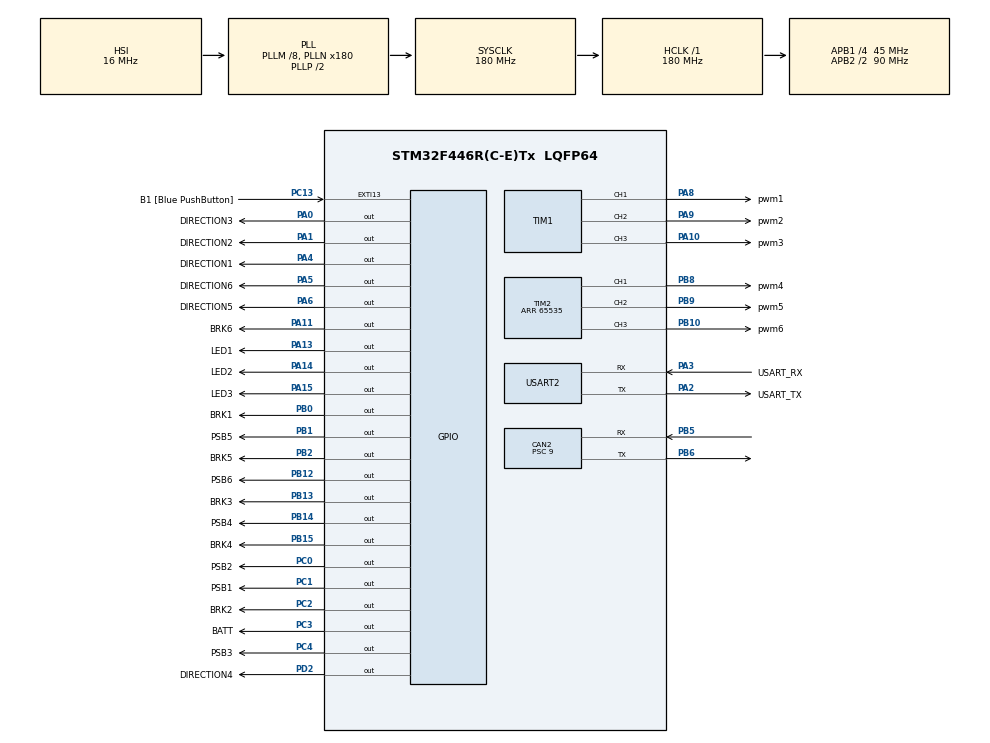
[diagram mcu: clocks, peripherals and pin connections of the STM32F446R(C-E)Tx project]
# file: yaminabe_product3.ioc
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CAN2.BS1=CAN_BS1_4TQ
CAN2.BS2=CAN_BS2_5TQ
CAN2.CalculateBaudRate=500000
CAN2.CalculateTimeBit=2000
CAN2.CalculateTimeQuantum=200.0
CAN2.Prescaler=9
CAN2.SJW=CAN_SJW_4TQ
Mcu.Family=STM32F4
Mcu.Name=STM32F446R(C-E)Tx
Mcu.Package=LQFP64
NVIC.CAN2_RX0_IRQn=true\:0\:0\:false\:false\:true\:true\:true\:true
NVIC.CAN2_RX1_IRQn=true\:0\:0\:false\:false\:true\:true\:true\:true
NVIC.CAN2_TX_IRQn=true\:0\:0\:false\:false\:true\:true\:true\:true
NVIC.PriorityGroup=NVIC_PRIORITYGROUP_0
PA0-WKUP.GPIO_Label=DIRECTION3
PA0-WKUP.Signal=GPIO_Output
PA1.GPIO_Label=DIRECTION2
PA1.Signal=GPIO_Output
PA10.GPIO_Label=pwm3
PA10.Signal=S_TIM1_CH3
PA11.GPIO_Label=BRK6
PA11.Signal=GPIO_Output
PA13.GPIO_Label=LED1
PA13.Signal=GPIO_Output
PA14.GPIO_Label=LED2
PA14.Signal=GPIO_Output
PA15.GPIO_Label=LED3
PA15.Signal=GPIO_Output
PA2.GPIO_Label=USART_TX
PA2.Mode=Asynchronous
PA2.Signal=USART2_TX
PA3.GPIO_Label=USART_RX
PA3.Mode=Asynchronous
PA3.Signal=USART2_RX
PA4.GPIO_Label=DIRECTION1
PA4.Signal=GPIO_Output
PA5.GPIO_Label=DIRECTION6
PA5.Signal=GPIO_Output
PA6.GPIO_Label=DIRECTION5
PA6.Signal=GPIO_Output
PA8.GPIO_Label=pwm1
PA8.Signal=S_TIM1_CH1
PA9.GPIO_Label=pwm2
PA9.Signal=S_TIM1_CH2
PB0.GPIO_Label=BRK1
PB0.Signal=GPIO_Output
PB1.GPIO_Label=PSB5
PB1.Signal=GPIO_Output
PB10.GPIO_Label=pwm6
PB10.Signal=S_TIM2_CH3
PB12.GPIO_Label=PSB6
PB12.Signal=GPIO_Output
PB13.GPIO_Label=BRK3
PB13.Signal=GPIO_Output
PB14.GPIO_Label=PSB4
PB14.Signal=GPIO_Output
PB15.GPIO_Label=BRK4
PB15.Signal=GPIO_Output
PB2.GPIO_Label=BRK5
PB2.Signal=GPIO_Output
PB3.Signal=SYS_JTDO-SWO
PB5.Mode=CAN_Activate
PB5.Signal=CAN2_RX
PB6.Mode=CAN_Activate
PB6.Signal=CAN2_TX
PB8.GPIO_Label=pwm4
PB8.Signal=S_TIM2_CH1_ETR
PB9.GPIO_Label=pwm5
PB9.Signal=S_TIM2_CH2
PC0.GPIO_Label=PSB2
PC0.Signal=GPIO_Output
PC1.GPIO_Label=PSB1
PC1.Signal=GPIO_Output
PC13.GPIO_Label=B1 [Blue PushButton]
PC13.GPIO_ModeDefaultEXTI=GPIO_MODE_IT_FALLING
PC13.Signal=GPXTI13
PC14-OSC32_IN.Mode=LSE-External-Oscillator
PC14-OSC32_IN.Signal=RCC_OSC32_IN
PC15-OSC32_OUT.Mode=LSE-External-Oscillator
PC15-OSC32_OUT.Signal=RCC_OSC32_OUT
PC2.GPIO_Label=BRK2
PC2.Signal=GPIO_Output
PC3.GPIO_Label=BATT
PC3.Signal=GPIO_Output
PC4.GPIO_Label=PSB3
PC4.Signal=GPIO_Output
PD2.GPIO_Label=DIRECTION4
PD2.Signal=GPIO_Output
PH0-OSC_IN.Mode=HSE-External-Oscillator
PH0-OSC_IN.Signal=RCC_OSC_IN
PH1-OSC_OUT.Mode=HSE-External-Oscillator
PH1-OSC_OUT.Signal=RCC_OSC_OUT
ProjectManager.HeapSize=0x200
ProjectManager.StackSize=0x400
ProjectManager.TargetToolchain=STM32CubeIDE
RCC.48MHZClocksFreq_Value=84000000
RCC.AHBFreq_Value=180000000
RCC.APB1CLKDivider=RCC_HCLK_DIV4
RCC.APB1Freq_Value=45000000
RCC.APB1TimFreq_Value=90000000
RCC.APB2CLKDivider=RCC_HCLK_DIV2
RCC.APB2Freq_Value=90000000
RCC.APB2TimFreq_Value=180000000
RCC.CortexFreq_Value=180000000
RCC.FLatency-AdvancedSettings=FLASH_LATENCY_5
RCC.HCLKFreq_Value=180000000
RCC.HSE_VALUE=8000000
RCC.HSI_VALUE=16000000
RCC.PLLM=8
RCC.PLLN=180
RCC.SYSCLKFreq_VALUE=180000000
RCC.SYSCLKSource=RCC_SYSCLKSOURCE_PLLCLK
RCC.USBFreq_Value=180000000
RCC.VCOOutputFreq_Value=360000000
SH.S_TIM1_CH1.0=TIM1_CH1,PWM Generation1 CH1
SH.S_TIM1_CH2.0=TIM1_CH2,PWM Generation2 CH2
SH.S_TIM1_CH3.0=TIM1_CH3,PWM Generation3 CH3
SH.S_TIM2_CH1_ETR.0=TIM2_CH1,PWM Generation1 CH1
SH.S_TIM2_CH2.0=TIM2_CH2,PWM Generation2 CH2
SH.S_TIM2_CH3.0=TIM2_CH3,PWM Generation3 CH3
TIM1.Channel-PWM\ Generation1\ CH1=TIM_CHANNEL_1
TIM1.Channel-PWM\ Generation2\ CH2=TIM_CHANNEL_2
TIM1.Channel-PWM\ Generation3\ CH3=TIM_CHANNEL_3
TIM2.Channel-PWM\ Generation1\ CH1=TIM_CHANNEL_1
TIM2.Channel-PWM\ Generation2\ CH2=TIM_CHANNEL_2
TIM2.Channel-PWM\ Generation3\ CH3=TIM_CHANNEL_3
TIM2.Period=65535
USART2.VirtualMode=VM_ASYNC
VP_TIM1_VS_ClockSourceINT.Mode=Internal
VP_TIM2_VS_ClockSourceINT.Mode=Internal
board=NUCLEO-F446RE

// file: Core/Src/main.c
/* USER CODE BEGIN Header */
/**
  ******************************************************************************
  * @file           : main.c
  * @brief          : Main program body
  ******************************************************************************
  * @attention
  *
  * Copyright (c) 2023 STMicroelectronics.
  * All rights reserved.
  *
  * This software is licensed under terms that can be found in the LICENSE file
  * in the root directory of this software component.
  * If no LICENSE file comes with this software, it is provided AS-IS.
  *
  ******************************************************************************
  */
/* USER CODE END Header */
#include "main.h"

CAN_HandleTypeDef hcan2;

TIM_HandleTypeDef htim1;
TIM_HandleTypeDef htim2;

UART_HandleTypeDef huart2;

void SystemClock_Config(void);
static void MX_GPIO_Init(void);
static void MX_USART2_UART_Init(void);
static void MX_TIM1_Init(void);
static void MX_TIM2_Init(void);
static void MX_CAN2_Init(void);

int main(void)
{

  /* MCU Configuration--------------------------------------------------------*/

  /* Reset of all peripherals, Initializes the Flash interface and the Systick. */
  HAL_Init();

  /* Configure the system clock */
  SystemClock_Config();

  /* Initialize all configured peripherals */
  MX_GPIO_Init();
  MX_USART2_UART_Init();
  MX_TIM1_Init();
  MX_TIM2_Init();
  MX_CAN2_Init();
  /* USER CODE BEGIN 2 */
  HAL_TIM_PWM_Start(&htim1, TIM_CHANNEL_1);
  HAL_TIM_PWM_Start(&htim1, TIM_CHANNEL_2);
  /* USER CODE END 2 */

  /* Infinite loop */
  /* USER CODE BEGIN WHILE */
  while (1)
  {
	  HAL_GPIO_WritePin(GPIOC,PSB1_Pin,GPIO_PIN_SET);
	  HAL_GPIO_WritePin(GPIOB,BRK1_Pin,GPIO_PIN_RESET);
	  HAL_GPIO_WritePin(GPIOA,DIRECTION1_Pin,GPIO_PIN_SET);
	  __HAL_TIM_SET_COMPARE(&htim1, TIM_CHANNEL_1,60000);
	  HAL_Delay(1000);
	  HAL_GPIO_WritePin(GPIOA,DIRECTION1_Pin,GPIO_PIN_RESET);
	  __HAL_TIM_SET_COMPARE(&htim1, TIM_CHANNEL_1,30000);
	  HAL_Delay(1000);

    /* USER CODE END WHILE */

  }
}

void SystemClock_Config(void)
{
  RCC_OscInitTypeDef RCC_OscInitStruct = {0};
  RCC_ClkInitTypeDef RCC_ClkInitStruct = {0};

  /** Configure the main internal regulator output voltage
  */
  __HAL_RCC_PWR_CLK_ENABLE();
  __HAL_PWR_VOLTAGESCALING_CONFIG(PWR_REGULATOR_VOLTAGE_SCALE1);

  /** Initializes the RCC Oscillators according to the specified parameters
  * in the RCC_OscInitTypeDef structure.
  */
  RCC_OscInitStruct.OscillatorType = RCC_OSCILLATORTYPE_HSI;
  RCC_OscInitStruct.HSIState = RCC_HSI_ON;
  RCC_OscInitStruct.HSICalibrationValue = RCC_HSICALIBRATION_DEFAULT;
  RCC_OscInitStruct.PLL.PLLState = RCC_PLL_ON;
  RCC_OscInitStruct.PLL.PLLSource = RCC_PLLSOURCE_HSI;
  RCC_OscInitStruct.PLL.PLLM = 8;
  RCC_OscInitStruct.PLL.PLLN = 180;
  RCC_OscInitStruct.PLL.PLLP = RCC_PLLP_DIV2;
  RCC_OscInitStruct.PLL.PLLQ = 2;
  RCC_OscInitStruct.PLL.PLLR = 2;
  if (HAL_RCC_OscConfig(&RCC_OscInitStruct) != HAL_OK)
  {
    Error_Handler();
  }

  /** Activate the Over-Drive mode
  */
  if (HAL_PWREx_EnableOverDrive() != HAL_OK)
  {
    Error_Handler();
  }

  /** Initializes the CPU, AHB and APB buses clocks
  */
  RCC_ClkInitStruct.ClockType = RCC_CLOCKTYPE_HCLK|RCC_CLOCKTYPE_SYSCLK
                              |RCC_CLOCKTYPE_PCLK1|RCC_CLOCKTYPE_PCLK2;
  RCC_ClkInitStruct.SYSCLKSource = RCC_SYSCLKSOURCE_PLLCLK;
  RCC_ClkInitStruct.AHBCLKDivider = RCC_SYSCLK_DIV1;
  RCC_ClkInitStruct.APB1CLKDivider = RCC_HCLK_DIV4;
  RCC_ClkInitStruct.APB2CLKDivider = RCC_HCLK_DIV2;

  if (HAL_RCC_ClockConfig(&RCC_ClkInitStruct, FLASH_LATENCY_5) != HAL_OK)
  {
    Error_Handler();
  }
}

static void MX_CAN2_Init(void)
{

  hcan2.Instance = CAN2;
  hcan2.Init.Prescaler = 9;
  hcan2.Init.Mode = CAN_MODE_NORMAL;
  hcan2.Init.SyncJumpWidth = CAN_SJW_4TQ;
  hcan2.Init.TimeSeg1 = CAN_BS1_4TQ;
  hcan2.Init.TimeSeg2 = CAN_BS2_5TQ;
  hcan2.Init.TimeTriggeredMode = DISABLE;
  hcan2.Init.AutoBusOff = DISABLE;
  hcan2.Init.AutoWakeUp = DISABLE;
  hcan2.Init.AutoRetransmission = DISABLE;
  hcan2.Init.ReceiveFifoLocked = DISABLE;
  hcan2.Init.TransmitFifoPriority = DISABLE;
  if (HAL_CAN_Init(&hcan2) != HAL_OK)
  {
    Error_Handler();
  }

}

static void MX_TIM1_Init(void)
{

  TIM_ClockConfigTypeDef sClockSourceConfig = {0};
  TIM_MasterConfigTypeDef sMasterConfig = {0};
  TIM_OC_InitTypeDef sConfigOC = {0};
  TIM_BreakDeadTimeConfigTypeDef sBreakDeadTimeConfig = {0};

  htim1.Instance = TIM1;
  htim1.Init.Prescaler = 0;
  htim1.Init.CounterMode = TIM_COUNTERMODE_UP;
  htim1.Init.Period = 65535;
  htim1.Init.ClockDivision = TIM_CLOCKDIVISION_DIV1;
  htim1.Init.RepetitionCounter = 0;
  htim1.Init.AutoReloadPreload = TIM_AUTORELOAD_PRELOAD_DISABLE;
  if (HAL_TIM_Base_Init(&htim1) != HAL_OK)
  {
    Error_Handler();
  }
  sClockSourceConfig.ClockSource = TIM_CLOCKSOURCE_INTERNAL;
  if (HAL_TIM_ConfigClockSource(&htim1, &sClockSourceConfig) != HAL_OK)
  {
    Error_Handler();
  }
  if (HAL_TIM_PWM_Init(&htim1) != HAL_OK)
  {
    Error_Handler();
  }
  sMasterConfig.MasterOutputTrigger = TIM_TRGO_RESET;
  sMasterConfig.MasterSlaveMode = TIM_MASTERSLAVEMODE_DISABLE;
  if (HAL_TIMEx_MasterConfigSynchronization(&htim1, &sMasterConfig) != HAL_OK)
  {
    Error_Handler();
  }
  sConfigOC.OCMode = TIM_OCMODE_PWM1;
  sConfigOC.Pulse = 0;
  sConfigOC.OCPolarity = TIM_OCPOLARITY_HIGH;
  sConfigOC.OCNPolarity = TIM_OCNPOLARITY_HIGH;
  sConfigOC.OCFastMode = TIM_OCFAST_DISABLE;
  sConfigOC.OCIdleState = TIM_OCIDLESTATE_RESET;
  sConfigOC.OCNIdleState = TIM_OCNIDLESTATE_RESET;
  if (HAL_TIM_PWM_ConfigChannel(&htim1, &sConfigOC, TIM_CHANNEL_1) != HAL_OK)
  {
    Error_Handler();
  }
  if (HAL_TIM_PWM_ConfigChannel(&htim1, &sConfigOC, TIM_CHANNEL_2) != HAL_OK)
  {
    Error_Handler();
  }
  if (HAL_TIM_PWM_ConfigChannel(&htim1, &sConfigOC, TIM_CHANNEL_3) != HAL_OK)
  {
    Error_Handler();
  }
  sBreakDeadTimeConfig.OffStateRunMode = TIM_OSSR_DISABLE;
  sBreakDeadTimeConfig.OffStateIDLEMode = TIM_OSSI_DISABLE;
  sBreakDeadTimeConfig.LockLevel = TIM_LOCKLEVEL_OFF;
  sBreakDeadTimeConfig.DeadTime = 0;
  sBreakDeadTimeConfig.BreakState = TIM_BREAK_DISABLE;
  sBreakDeadTimeConfig.BreakPolarity = TIM_BREAKPOLARITY_HIGH;
  sBreakDeadTimeConfig.AutomaticOutput = TIM_AUTOMATICOUTPUT_DISABLE;
  if (HAL_TIMEx_ConfigBreakDeadTime(&htim1, &sBreakDeadTimeConfig) != HAL_OK)
  {
    Error_Handler();
  }
  HAL_TIM_MspPostInit(&htim1);

}

static void MX_TIM2_Init(void)
{

  TIM_ClockConfigTypeDef sClockSourceConfig = {0};
  TIM_MasterConfigTypeDef sMasterConfig = {0};
  TIM_OC_InitTypeDef sConfigOC = {0};

  htim2.Instance = TIM2;
  htim2.Init.Prescaler = 0;
  htim2.Init.CounterMode = TIM_COUNTERMODE_UP;
  htim2.Init.Period = 65535;
  htim2.Init.ClockDivision = TIM_CLOCKDIVISION_DIV1;
  htim2.Init.AutoReloadPreload = TIM_AUTORELOAD_PRELOAD_DISABLE;
  if (HAL_TIM_Base_Init(&htim2) != HAL_OK)
  {
    Error_Handler();
  }
  sClockSourceConfig.ClockSource = TIM_CLOCKSOURCE_INTERNAL;
  if (HAL_TIM_ConfigClockSource(&htim2, &sClockSourceConfig) != HAL_OK)
  {
    Error_Handler();
  }
  if (HAL_TIM_PWM_Init(&htim2) != HAL_OK)
  {
    Error_Handler();
  }
  sMasterConfig.MasterOutputTrigger = TIM_TRGO_RESET;
  sMasterConfig.MasterSlaveMode = TIM_MASTERSLAVEMODE_DISABLE;
  if (HAL_TIMEx_MasterConfigSynchronization(&htim2, &sMasterConfig) != HAL_OK)
  {
    Error_Handler();
  }
  sConfigOC.OCMode = TIM_OCMODE_PWM1;
  sConfigOC.Pulse = 0;
  sConfigOC.OCPolarity = TIM_OCPOLARITY_HIGH;
  sConfigOC.OCFastMode = TIM_OCFAST_DISABLE;
  if (HAL_TIM_PWM_ConfigChannel(&htim2, &sConfigOC, TIM_CHANNEL_1) != HAL_OK)
  {
    Error_Handler();
  }
  if (HAL_TIM_PWM_ConfigChannel(&htim2, &sConfigOC, TIM_CHANNEL_2) != HAL_OK)
  {
    Error_Handler();
  }
  if (HAL_TIM_PWM_ConfigChannel(&htim2, &sConfigOC, TIM_CHANNEL_3) != HAL_OK)
  {
    Error_Handler();
  }
  HAL_TIM_MspPostInit(&htim2);

}

static void MX_USART2_UART_Init(void)
{

  huart2.Instance = USART2;
  huart2.Init.BaudRate = 115200;
  huart2.Init.WordLength = UART_WORDLENGTH_8B;
  huart2.Init.StopBits = UART_STOPBITS_1;
  huart2.Init.Parity = UART_PARITY_NONE;
  huart2.Init.Mode = UART_MODE_TX_RX;
  huart2.Init.HwFlowCtl = UART_HWCONTROL_NONE;
  huart2.Init.OverSampling = UART_OVERSAMPLING_16;
  if (HAL_UART_Init(&huart2) != HAL_OK)
  {
    Error_Handler();
  }

}

static void MX_GPIO_Init(void)
{
  GPIO_InitTypeDef GPIO_InitStruct = {0};

  /* GPIO Ports Clock Enable */
  __HAL_RCC_GPIOC_CLK_ENABLE();
  __HAL_RCC_GPIOH_CLK_ENABLE();
  __HAL_RCC_GPIOA_CLK_ENABLE();
  __HAL_RCC_GPIOB_CLK_ENABLE();
  __HAL_RCC_GPIOD_CLK_ENABLE();

  /*Configure GPIO pin Output Level */
  HAL_GPIO_WritePin(GPIOC, PSB2_Pin|PSB1_Pin|BRK2_Pin|BATT_Pin
                          |PSB3_Pin, GPIO_PIN_RESET);

  /*Configure GPIO pin Output Level */
  HAL_GPIO_WritePin(GPIOA, DIRECTION3_Pin|DIRECTION2_Pin|DIRECTION1_Pin|DIRECTION6_Pin
                          |DIRECTION5_Pin|BRK6_Pin|LED1_Pin|LED2_Pin
                          |LED3_Pin, GPIO_PIN_RESET);

  /*Configure GPIO pin Output Level */
  HAL_GPIO_WritePin(GPIOB, BRK1_Pin|PSB5_Pin|BRK5_Pin|PSB6_Pin
                          |BRK3_Pin|PSB4_Pin|BRK4_Pin, GPIO_PIN_RESET);

  /*Configure GPIO pin Output Level */
  HAL_GPIO_WritePin(DIRECTION4_GPIO_Port, DIRECTION4_Pin, GPIO_PIN_RESET);

  /*Configure GPIO pin : B1_Pin */
  GPIO_InitStruct.Pin = B1_Pin;
  GPIO_InitStruct.Mode = GPIO_MODE_IT_FALLING;
  GPIO_InitStruct.Pull = GPIO_NOPULL;
  HAL_GPIO_Init(B1_GPIO_Port, &GPIO_InitStruct);

  /*Configure GPIO pins : PSB2_Pin PSB1_Pin BRK2_Pin BATT_Pin
                           PSB3_Pin */
  GPIO_InitStruct.Pin = PSB2_Pin|PSB1_Pin|BRK2_Pin|BATT_Pin
                          |PSB3_Pin;
  GPIO_InitStruct.Mode = GPIO_MODE_OUTPUT_PP;
  GPIO_InitStruct.Pull = GPIO_NOPULL;
  GPIO_InitStruct.Speed = GPIO_SPEED_FREQ_LOW;
  HAL_GPIO_Init(GPIOC, &GPIO_InitStruct);

  /*Configure GPIO pins : DIRECTION3_Pin DIRECTION2_Pin DIRECTION1_Pin DIRECTION6_Pin
                           DIRECTION5_Pin BRK6_Pin LED1_Pin LED2_Pin
                           LED3_Pin */
  GPIO_InitStruct.Pin = DIRECTION3_Pin|DIRECTION2_Pin|DIRECTION1_Pin|DIRECTION6_Pin
                          |DIRECTION5_Pin|BRK6_Pin|LED1_Pin|LED2_Pin
                          |LED3_Pin;
  GPIO_InitStruct.Mode = GPIO_MODE_OUTPUT_PP;
  GPIO_InitStruct.Pull = GPIO_NOPULL;
  GPIO_InitStruct.Speed = GPIO_SPEED_FREQ_LOW;
  HAL_GPIO_Init(GPIOA, &GPIO_InitStruct);

  /*Configure GPIO pins : BRK1_Pin PSB5_Pin BRK5_Pin PSB6_Pin
                           BRK3_Pin PSB4_Pin BRK4_Pin */
  GPIO_InitStruct.Pin = BRK1_Pin|PSB5_Pin|BRK5_Pin|PSB6_Pin
                          |BRK3_Pin|PSB4_Pin|BRK4_Pin;
  GPIO_InitStruct.Mode = GPIO_MODE_OUTPUT_PP;
  GPIO_InitStruct.Pull = GPIO_NOPULL;
  GPIO_InitStruct.Speed = GPIO_SPEED_FREQ_LOW;
  HAL_GPIO_Init(GPIOB, &GPIO_InitStruct);

  /*Configure GPIO pin : DIRECTION4_Pin */
  GPIO_InitStruct.Pin = DIRECTION4_Pin;
  GPIO_InitStruct.Mode = GPIO_MODE_OUTPUT_PP;
  GPIO_InitStruct.Pull = GPIO_NOPULL;
  GPIO_InitStruct.Speed = GPIO_SPEED_FREQ_LOW;
  HAL_GPIO_Init(DIRECTION4_GPIO_Port, &GPIO_InitStruct);

}

void Error_Handler(void)
{
  __disable_irq();
  while (1)
  {
  }
}
